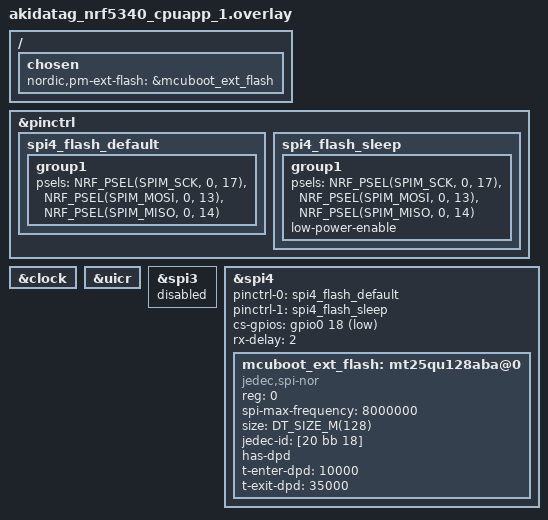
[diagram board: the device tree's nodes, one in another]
/*
 * MCUboot on revision 1 reaches flash IC1 through SPIM4 on the SPIM3 pins, and
 * leaves the audio clock and the NFC pins to the application.
 */

&pinctrl {
	spi4_flash_default: spi4_flash_default {
		group1 {
			psels = <NRF_PSEL(SPIM_SCK, 0, 17)>,
				<NRF_PSEL(SPIM_MOSI, 0, 13)>,
				<NRF_PSEL(SPIM_MISO, 0, 14)>;
		};
	};

	spi4_flash_sleep: spi4_flash_sleep {
		group1 {
			psels = <NRF_PSEL(SPIM_SCK, 0, 17)>,
				<NRF_PSEL(SPIM_MOSI, 0, 13)>,
				<NRF_PSEL(SPIM_MISO, 0, 14)>;
			low-power-enable;
		};
	};
};

/ {
	chosen {
		nordic,pm-ext-flash = &mcuboot_ext_flash;
	};
};

&clock {
	/delete-property/ hfclkaudio-frequency;
};

&uicr {
	/delete-property/ nfct-pins-as-gpios;
};

/delete-node/ &camera;
/delete-node/ &ext_flash;

&spi3 {
	status = "disabled";
	/delete-property/ cs-gpios;
};

/delete-node/ &akd;
/delete-node/ &akd_flash;

&spi4 {
	pinctrl-0 = <&spi4_flash_default>;
	pinctrl-1 = <&spi4_flash_sleep>;
	cs-gpios = <&gpio0 18 GPIO_ACTIVE_LOW>;
	/* The SoC default, in place of the AKD1500 sample delay */
	rx-delay = <2>;

	mcuboot_ext_flash: mt25qu128aba@0 {
		compatible = "jedec,spi-nor";
		reg = <0>;
		spi-max-frequency = <8000000>;
		size = <DT_SIZE_M(128)>;
		jedec-id = [20 bb 18];
		has-dpd;
		t-enter-dpd = <10000>;
		t-exit-dpd = <35000>;
	};
};
